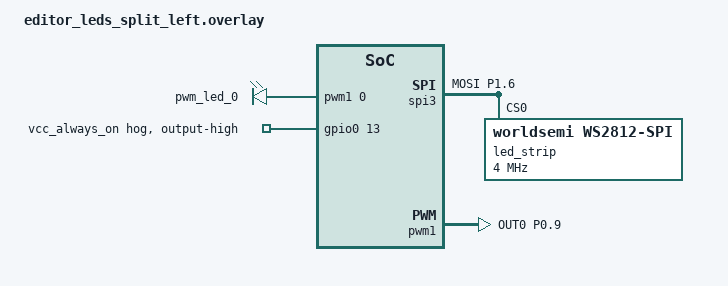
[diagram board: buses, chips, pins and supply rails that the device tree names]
/* Generated by ZMK Editor from editor_leds_split.editor.json. */

#include "editor_leds_split.dtsi"

&kscan0 {
    row-gpios
        = <&pro_micro  4 (GPIO_ACTIVE_HIGH | GPIO_PULL_DOWN)>
        , <&pro_micro  5 (GPIO_ACTIVE_HIGH | GPIO_PULL_DOWN)>
        , <&pro_micro  6 (GPIO_ACTIVE_HIGH | GPIO_PULL_DOWN)>
        ;

    col-gpios
        = <&pro_micro 21 GPIO_ACTIVE_HIGH>
        , <&pro_micro 20 GPIO_ACTIVE_HIGH>
        , <&pro_micro 19 GPIO_ACTIVE_HIGH>
        , <&pro_micro 18 GPIO_ACTIVE_HIGH>
        , <&pro_micro 15 GPIO_ACTIVE_HIGH>
        , <&pro_micro 14 GPIO_ACTIVE_HIGH>
        ;
};

/ {
    chosen {
        zmk,underglow = &led_strip;
    };
};

&pinctrl {
    led_spi_default: led_spi_default {
        group1 {
            psels = <NRF_PSEL(SPIM_MOSI, 1, 6)>;
        };
    };
    led_spi_sleep: led_spi_sleep {
        group1 {
            psels = <NRF_PSEL(SPIM_MOSI, 1, 6)>;
            low-power-enable;
        };
    };
};

&spi3 {
    status = "okay";
    compatible = "nordic,nrf-spim";
    pinctrl-0 = <&led_spi_default>;
    pinctrl-1 = <&led_spi_sleep>;
    pinctrl-names = "default", "sleep";

    led_strip: ws2812@0 {
        compatible = "worldsemi,ws2812-spi";
        reg = <0>;
        spi-max-frequency = <4000000>;
        chain-length = <6>;
        spi-one-frame = <0x70>;
        spi-zero-frame = <0x40>;
        color-mapping = <LED_COLOR_ID_GREEN LED_COLOR_ID_RED LED_COLOR_ID_BLUE>;
    };
};

/ {
    chosen {
        zmk,backlight = &backlight;
    };

    backlight: backlight {
        compatible = "pwm-leds";
        pwm_led_0 {
            pwms = <&pwm1 0 PWM_MSEC(10) PWM_POLARITY_NORMAL>;
        };
    };
};

&pinctrl {
    backlight_pwm_default: backlight_pwm_default {
        group1 {
            psels = <NRF_PSEL(PWM_OUT0, 0, 9)>;
        };
    };
    backlight_pwm_sleep: backlight_pwm_sleep {
        group1 {
            psels = <NRF_PSEL(PWM_OUT0, 0, 9)>;
            low-power-enable;
        };
    };
};

&pwm1 {
    status = "okay";
    pinctrl-0 = <&backlight_pwm_default>;
    pinctrl-1 = <&backlight_pwm_sleep>;
    pinctrl-names = "default", "sleep";
};

/* ZMK's external power switches the LEDs' power; the board's own 3.3V pin stays on. */
&{/EXT_POWER} {
    control-gpios = <&pro_micro 8 GPIO_ACTIVE_HIGH>;
};

&gpio0 {
    vcc_always_on {
        gpio-hog;
        gpios = <13 GPIO_ACTIVE_HIGH>;
        output-high;
    };
};
